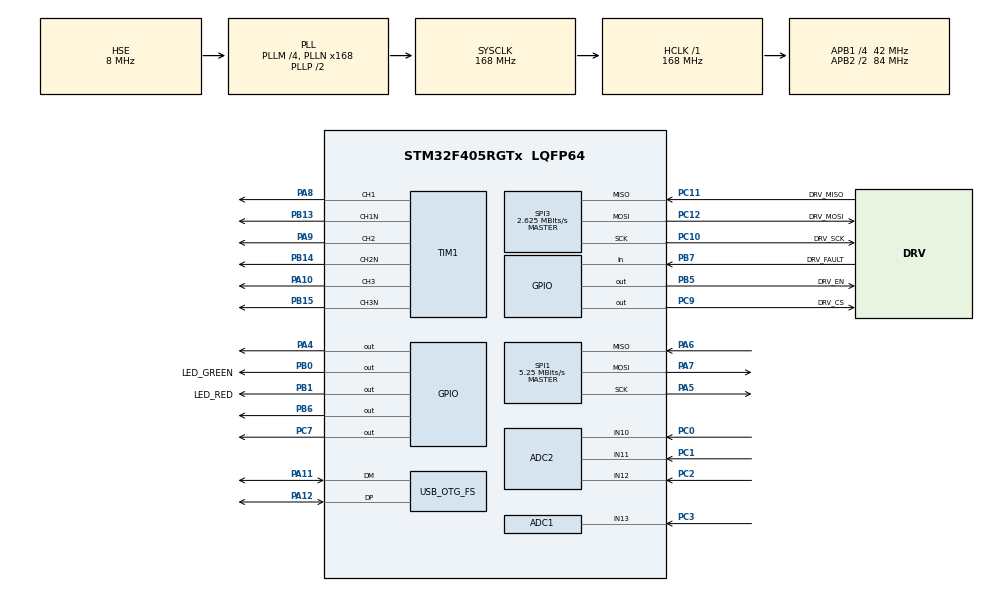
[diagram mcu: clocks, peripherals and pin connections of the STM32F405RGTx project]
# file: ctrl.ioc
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ADC1.Channel-0\#ChannelRegularConversion=ADC_CHANNEL_13
ADC1.ContinuousConvMode=ENABLE
ADC1.DMAContinuousRequests=ENABLE
ADC1.NbrOfConversionFlag=1
ADC1.Rank-0\#ChannelRegularConversion=1
ADC1.SamplingTime-0\#ChannelRegularConversion=ADC_SAMPLETIME_3CYCLES
ADC1.master=1
ADC2.Channel-0\#ChannelRegularConversion=ADC_CHANNEL_10
ADC2.Channel-1\#ChannelInjectedConversion=ADC_CHANNEL_10
ADC2.Channel-2\#ChannelInjectedConversion=ADC_CHANNEL_11
ADC2.Channel-3\#ChannelInjectedConversion=ADC_CHANNEL_12
ADC2.ContinuousConvMode=ENABLE
ADC2.ExternalTrigInjecConv=ADC_EXTERNALTRIGINJECCONV_T1_CC4
ADC2.ExternalTrigInjecConvEdge=ADC_EXTERNALTRIGINJECCONVEDGE_FALLING
ADC2.InjNumberOfConversion=3
ADC2.InjectedOffset-1\#ChannelInjectedConversion=0
ADC2.InjectedOffset-2\#ChannelInjectedConversion=0
ADC2.InjectedOffset-3\#ChannelInjectedConversion=0
ADC2.InjectedRank-1\#ChannelInjectedConversion=1
ADC2.InjectedRank-2\#ChannelInjectedConversion=2
ADC2.InjectedRank-3\#ChannelInjectedConversion=3
ADC2.NbrOfConversion=1
ADC2.NbrOfConversionFlag=1
ADC2.Rank-0\#ChannelRegularConversion=1
ADC2.SamplingTime-0\#ChannelRegularConversion=ADC_SAMPLETIME_3CYCLES
ADC2.SamplingTime-1\#ChannelInjectedConversion=ADC_SAMPLETIME_3CYCLES
ADC2.SamplingTime-2\#ChannelInjectedConversion=ADC_SAMPLETIME_3CYCLES
ADC2.SamplingTime-3\#ChannelInjectedConversion=ADC_SAMPLETIME_3CYCLES
Dma.ADC1.0.Direction=DMA_PERIPH_TO_MEMORY
Dma.ADC1.0.FIFOMode=DMA_FIFOMODE_DISABLE
Dma.ADC1.0.Instance=DMA2_Stream0
Dma.ADC1.0.MemDataAlignment=DMA_MDATAALIGN_HALFWORD
Dma.ADC1.0.MemInc=DMA_MINC_ENABLE
Dma.ADC1.0.Mode=DMA_CIRCULAR
Dma.ADC1.0.PeriphDataAlignment=DMA_PDATAALIGN_HALFWORD
Dma.ADC1.0.PeriphInc=DMA_PINC_DISABLE
Dma.ADC1.0.Priority=DMA_PRIORITY_LOW
Dma.Request0=ADC1
FREERTOS.Tasks01=defaultTask,24,128,StartDefaultTask,Default,NULL,Dynamic,NULL,NULL
FREERTOS.configUSE_NEWLIB_REENTRANT=1
Mcu.Family=STM32F4
Mcu.Name=STM32F405RGTx
Mcu.Package=LQFP64
Mcu.UserConstants=TIM_1_8_PERIOD_CLOCKS,4250;TIM_APB1_CLOCK_HZ,84000000;TIM_APB1_DEADTIME_CLOCKS,20;TIM_APB1_PERIOD_CLOCKS,4096;TIM_1_8_RCR,2;TIM_1_8_DEADTIME_CLOCKS,20;TIM_1_8_CLOCK_HZ,168000000
NVIC.DMA2_Stream0_IRQn=true\:5\:0\:false\:false\:true\:true\:false\:true\:true
NVIC.OTG_FS_IRQn=true\:5\:0\:false\:false\:true\:true\:false\:true\:true
NVIC.PriorityGroup=NVIC_PRIORITYGROUP_4
NVIC.TIM1_UP_TIM10_IRQn=true\:5\:0\:false\:false\:true\:true\:true\:true\:true
NVIC.TIM6_DAC_IRQn=true\:15\:0\:false\:false\:true\:false\:false\:true\:true
NVIC.TimeBase=TIM6_DAC_IRQn
NVIC.TimeBaseIP=TIM6
PA10.Signal=S_TIM1_CH3
PA11.Mode=Device_Only
PA11.Signal=USB_OTG_FS_DM
PA12.Mode=Device_Only
PA12.Signal=USB_OTG_FS_DP
PA13.Mode=Serial_Wire
PA13.Signal=SYS_JTMS-SWDIO
PA14.Mode=Serial_Wire
PA14.Signal=SYS_JTCK-SWCLK
PA4.Signal=GPIO_Output
PA5.Mode=Full_Duplex_Master
PA5.Signal=SPI1_SCK
PA6.Mode=Full_Duplex_Master
PA6.Signal=SPI1_MISO
PA7.Mode=Full_Duplex_Master
PA7.Signal=SPI1_MOSI
PA8.Signal=S_TIM1_CH1
PA9.Signal=S_TIM1_CH2
PB0.GPIO_Label=LED_GREEN
PB0.Signal=GPIO_Output
PB1.GPIO_Label=LED_RED
PB1.Signal=GPIO_Output
PB13.Mode=PWM Generation1 CH1 CH1N
PB13.Signal=TIM1_CH1N
PB14.Mode=PWM Generation2 CH2 CH2N
PB14.Signal=TIM1_CH2N
PB15.Mode=PWM Generation3 CH3 CH3N
PB15.Signal=TIM1_CH3N
PB5.GPIO_Label=DRV_EN
PB5.Signal=GPIO_Output
PB6.Signal=GPIO_Output
PB7.GPIO_Label=DRV_FAULT
PB7.Signal=GPIO_Input
PC0.Signal=ADCx_IN10
PC1.Signal=ADCx_IN11
PC10.GPIO_Label=DRV_SCK
PC10.Mode=Full_Duplex_Master
PC10.Signal=SPI3_SCK
PC11.GPIO_Label=DRV_MISO
PC11.Mode=Full_Duplex_Master
PC11.Signal=SPI3_MISO
PC12.GPIO_Label=DRV_MOSI
PC12.Mode=Full_Duplex_Master
PC12.Signal=SPI3_MOSI
PC2.Signal=ADCx_IN12
PC3.Signal=ADCx_IN13
PC7.Signal=GPIO_Output
PC9.GPIO_Label=DRV_CS
PC9.Signal=GPIO_Output
PH0-OSC_IN.Mode=HSE-External-Oscillator
PH0-OSC_IN.Signal=RCC_OSC_IN
PH1-OSC_OUT.Mode=HSE-External-Oscillator
PH1-OSC_OUT.Signal=RCC_OSC_OUT
ProjectManager.HeapSize=0x200
ProjectManager.StackSize=0x400
ProjectManager.TargetToolchain=STM32CubeIDE
RCC.48MHZClocksFreq_Value=48000000
RCC.AHBFreq_Value=168000000
RCC.APB1CLKDivider=RCC_HCLK_DIV4
RCC.APB1Freq_Value=42000000
RCC.APB1TimFreq_Value=84000000
RCC.APB2CLKDivider=RCC_HCLK_DIV2
RCC.APB2Freq_Value=84000000
RCC.APB2TimFreq_Value=168000000
RCC.CortexFreq_Value=168000000
RCC.HCLKFreq_Value=168000000
RCC.HSE_VALUE=8000000
RCC.HSI_VALUE=16000000
RCC.LSE_VALUE=32768
RCC.PLLM=4
RCC.PLLN=168
RCC.PLLQ=7
RCC.SYSCLKFreq_VALUE=168000000
RCC.SYSCLKSource=RCC_SYSCLKSOURCE_PLLCLK
RCC.VCOOutputFreq_Value=336000000
SH.ADCx_IN10.0=ADC2_IN10,IN10
SH.ADCx_IN11.0=ADC2_IN11,IN11
SH.ADCx_IN12.0=ADC2_IN12,IN12
SH.ADCx_IN13.0=ADC1_IN13,IN13
SH.S_TIM1_CH1.0=TIM1_CH1,PWM Generation1 CH1 CH1N
SH.S_TIM1_CH2.0=TIM1_CH2,PWM Generation2 CH2 CH2N
SH.S_TIM1_CH3.0=TIM1_CH3,PWM Generation3 CH3 CH3N
SPI1.BaudRatePrescaler=SPI_BAUDRATEPRESCALER_16
SPI1.CLKPhase=SPI_PHASE_2EDGE
SPI1.CLKPolarity=SPI_POLARITY_HIGH
SPI1.CalculateBaudRate=5.25 MBits/s
SPI1.DataSize=SPI_DATASIZE_16BIT
SPI1.Direction=SPI_DIRECTION_2LINES
SPI1.Mode=SPI_MODE_MASTER
SPI1.VirtualType=VM_MASTER
SPI3.BaudRatePrescaler=SPI_BAUDRATEPRESCALER_16
SPI3.CLKPhase=SPI_PHASE_2EDGE
SPI3.CalculateBaudRate=2.625 MBits/s
SPI3.DataSize=SPI_DATASIZE_16BIT
SPI3.Direction=SPI_DIRECTION_2LINES
SPI3.Mode=SPI_MODE_MASTER
SPI3.VirtualType=VM_MASTER
STMicroelectronics.X-CUBE-ALGOBUILD.1.4.0.LibraryCcDSPOoLibraryJjDSPOoLibrary=true
TIM1.Channel-PWM\ Generation1\ CH1\ CH1N=TIM_CHANNEL_1
TIM1.Channel-PWM\ Generation2\ CH2\ CH2N=TIM_CHANNEL_2
TIM1.Channel-PWM\ Generation3\ CH3\ CH3N=TIM_CHANNEL_3
TIM1.Channel-PWM\ Generation4\ No\ Output=TIM_CHANNEL_4
TIM1.CounterMode=TIM_COUNTERMODE_CENTERALIGNED1
TIM1.DeadTime=TIM_1_8_DEADTIME_CLOCKS
TIM1.OCMode_PWM-PWM\ Generation1\ CH1\ CH1N=TIM_OCMODE_PWM1
TIM1.OCMode_PWM-PWM\ Generation2\ CH2\ CH2N=TIM_OCMODE_PWM1
TIM1.OCMode_PWM-PWM\ Generation3\ CH3\ CH3N=TIM_OCMODE_PWM1
TIM1.OffStateIDLEMode=TIM_OSSI_ENABLE
TIM1.OffStateRunMode=TIM_OSSR_ENABLE
TIM1.Period=TIM_1_8_PERIOD_CLOCKS
TIM1.Pulse-PWM\ Generation4\ No\ Output=3499
TIM1.RepetitionCounter=TIM_1_8_RCR
TIM1.TIM_MasterOutputTrigger=TIM_TRGO_RESET
USB_DEVICE.CLASS_NAME_FS=CDC
USB_DEVICE.VirtualMode-CDC_FS=Cdc
USB_DEVICE.VirtualModeFS=Cdc_FS
USB_OTG_FS.VirtualMode=Device_Only
VP_FREERTOS_VS_CMSIS_V2.Mode=CMSIS_V2
VP_STMicroelectronics.X-CUBE-ALGOBUILD_VS_DSPOoLibraryJjLibrary_1.4.0_1.4.0.Mode=DSPOoLibraryJjLibrary
VP_SYS_VS_tim6.Mode=TIM6
VP_TIM1_VS_ClockSourceINT.Mode=Internal
VP_TIM1_VS_no_output4.Mode=PWM Generation4 No Output
VP_USB_DEVICE_VS_USB_DEVICE_CDC_FS.Mode=CDC_FS
board=custom

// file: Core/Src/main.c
/* USER CODE BEGIN Header */
/**
  ******************************************************************************
  * @file           : main.c
  * @brief          : Main program body
  ******************************************************************************
  * @attention
  *
  * Copyright (c) 2024 STMicroelectronics.
  * All rights reserved.
  *
  * This software is licensed under terms that can be found in the LICENSE file
  * in the root directory of this software component.
  * If no LICENSE file comes with this software, it is provided AS-IS.
  *
  ******************************************************************************
  */
/* USER CODE END Header */
#include "main.h"
#include "cmsis_os.h"
#include "adc.h"
#include "dma.h"
#include "spi.h"
#include "tim.h"
#include "usb_device.h"
#include "gpio.h"

/* USER CODE BEGIN Includes */
#include "board.h"
/* USER CODE END Includes */

void SystemClock_Config(void);
void MX_FREERTOS_Init(void);

/* USER CODE BEGIN 0 */
#if 0
/* USER CODE END 0 */

int main(void)
{

  /* MCU Configuration--------------------------------------------------------*/

  /* Reset of all peripherals, Initializes the Flash interface and the Systick. */
  HAL_Init();

  /* Configure the system clock */
  SystemClock_Config();

  /* Initialize all configured peripherals */
  MX_GPIO_Init();
  MX_DMA_Init();
  MX_SPI3_Init();
  MX_SPI1_Init();
  MX_TIM1_Init();
  MX_ADC2_Init();
  MX_ADC1_Init();

  /* Init scheduler */
  osKernelInitialize();

  /* Call init function for freertos objects (in cmsis_os2.c) */
  MX_FREERTOS_Init();

  /* Start scheduler */
  osKernelStart();

  /* We should never get here as control is now taken by the scheduler */

  /* Infinite loop */
  while (1)
  {

  }
}
#endif
void SystemClock_Config(void)
{
  RCC_OscInitTypeDef RCC_OscInitStruct = {0};
  RCC_ClkInitTypeDef RCC_ClkInitStruct = {0};

  /** Configure the main internal regulator output voltage
  */
  __HAL_RCC_PWR_CLK_ENABLE();
  __HAL_PWR_VOLTAGESCALING_CONFIG(PWR_REGULATOR_VOLTAGE_SCALE1);

  /** Initializes the RCC Oscillators according to the specified parameters
  * in the RCC_OscInitTypeDef structure.
  */
  RCC_OscInitStruct.OscillatorType = RCC_OSCILLATORTYPE_HSE;
  RCC_OscInitStruct.HSEState = RCC_HSE_ON;
  RCC_OscInitStruct.PLL.PLLState = RCC_PLL_ON;
  RCC_OscInitStruct.PLL.PLLSource = RCC_PLLSOURCE_HSE;
  RCC_OscInitStruct.PLL.PLLM = 4;
  RCC_OscInitStruct.PLL.PLLN = 168;
  RCC_OscInitStruct.PLL.PLLP = RCC_PLLP_DIV2;
  RCC_OscInitStruct.PLL.PLLQ = 7;
  if (HAL_RCC_OscConfig(&RCC_OscInitStruct) != HAL_OK)
  {
    Error_Handler();
  }

  /** Initializes the CPU, AHB and APB buses clocks
  */
  RCC_ClkInitStruct.ClockType = RCC_CLOCKTYPE_HCLK|RCC_CLOCKTYPE_SYSCLK
                              |RCC_CLOCKTYPE_PCLK1|RCC_CLOCKTYPE_PCLK2;
  RCC_ClkInitStruct.SYSCLKSource = RCC_SYSCLKSOURCE_PLLCLK;
  RCC_ClkInitStruct.AHBCLKDivider = RCC_SYSCLK_DIV1;
  RCC_ClkInitStruct.APB1CLKDivider = RCC_HCLK_DIV4;
  RCC_ClkInitStruct.APB2CLKDivider = RCC_HCLK_DIV2;

  if (HAL_RCC_ClockConfig(&RCC_ClkInitStruct, FLASH_LATENCY_5) != HAL_OK)
  {
    Error_Handler();
  }
}

void HAL_TIM_PeriodElapsedCallback(TIM_HandleTypeDef *htim)
{
  if (htim->Instance == TIM6) {
    HAL_IncTick();
  }
  /* USER CODE BEGIN Callback 1 */
  if(htim->Instance == TIM1) {
    control_loop_irq_handler();
  }
  /* USER CODE END Callback 1 */
}

void Error_Handler(void)
{
  __disable_irq();
  while (1)
  {
  }
}
